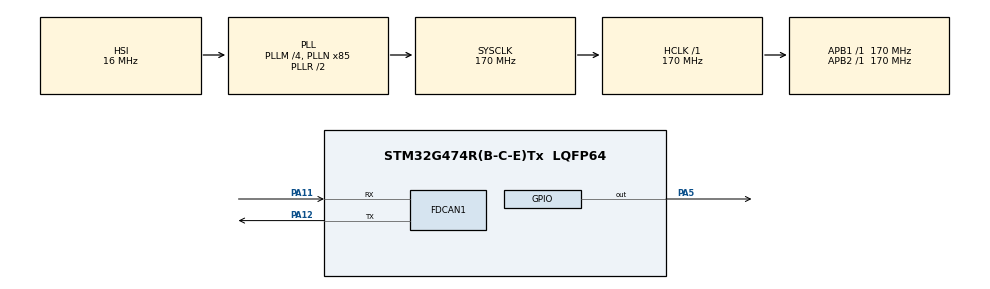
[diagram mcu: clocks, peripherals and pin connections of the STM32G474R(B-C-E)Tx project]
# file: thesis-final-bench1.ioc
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FDCAN1.CalculateBaudRateNominal=500000
FDCAN1.CalculateTimeBitNominal=2000
FDCAN1.CalculateTimeQuantumNominal=100.0
FDCAN1.NominalPrescaler=17
FDCAN1.NominalTimeSeg1=15
FDCAN1.NominalTimeSeg2=4
Mcu.Family=STM32G4
Mcu.Name=STM32G474R(B-C-E)Tx
Mcu.Package=LQFP64
NVIC.PriorityGroup=NVIC_PRIORITYGROUP_4
PA11.Mode=FDCAN_Activate
PA11.Signal=FDCAN1_RX
PA12.Mode=FDCAN_Activate
PA12.Signal=FDCAN1_TX
PA5.Signal=GPIO_Output
ProjectManager.HeapSize=0x200
ProjectManager.StackSize=0x400
ProjectManager.TargetToolchain=STM32CubeIDE
RCC.ADC12Freq_Value=170000000
RCC.ADC345Freq_Value=170000000
RCC.AHBFreq_Value=170000000
RCC.APB1Freq_Value=170000000
RCC.APB1TimFreq_Value=170000000
RCC.APB2Freq_Value=170000000
RCC.APB2TimFreq_Value=170000000
RCC.CortexFreq_Value=170000000
RCC.EXTERNAL_CLOCK_VALUE=12288000
RCC.HCLKFreq_Value=170000000
RCC.HSE_VALUE=8000000
RCC.HSI48_VALUE=48000000
RCC.HSI_VALUE=16000000
RCC.LSE_VALUE=32768
RCC.PLLM=RCC_PLLM_DIV4
RCC.PLLN=85
RCC.SYSCLKFreq_VALUE=170000000
RCC.SYSCLKSource=RCC_SYSCLKSOURCE_PLLCLK
RCC.USBFreq_Value=170000000
RCC.VCOOutputFreq_Value=340000000
VP_SYS_VS_DBSignals.Mode=DisableDeadBatterySignals
board=custom

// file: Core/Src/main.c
/* USER CODE BEGIN Header */
/**
  ******************************************************************************
  * @file           : main.c
  * @brief          : Main program body
  ******************************************************************************
  * @attention
  *
  * Copyright (c) 2026 STMicroelectronics.
  * All rights reserved.
  *
  * This software is licensed under terms that can be found in the LICENSE file
  * in the root directory of this software component.
  * If no LICENSE file comes with this software, it is provided AS-IS.
  *
  ******************************************************************************
  */
/* USER CODE END Header */
#include "main.h"

/* USER CODE BEGIN Includes */
#include "can.h"
#include "scheduler.h"
#include "com_manager.h"
#include "diagnostics.h"
#include "motor_control.h"

/* USER CODE END Includes */

FDCAN_HandleTypeDef hfdcan1;

void SystemClock_Config(void);
static void MX_GPIO_Init(void);
static void MX_FDCAN1_Init(void);

int main(void)
{

  /* MCU Configuration--------------------------------------------------------*/

  /* Reset of all peripherals, Initializes the Flash interface and the Systick. */
  HAL_Init();

  /* Configure the system clock */
  SystemClock_Config();

  /* Initialize all configured peripherals */
  MX_GPIO_Init();
  MX_FDCAN1_Init();
  /* USER CODE BEGIN 2 */
  CAN_Init();
  Scheduler_Init();
  Diagnostics_Init();
  App_MotorControl_Init();
  /* USER CODE END 2 */

  /* Infinite loop */
  /* USER CODE BEGIN WHILE */
  float actual_speed_rpm = 1500.0f; // Mocking physical encoder feedback for now

  while (1)
  {
      // --- 10ms TASK: Motor Control & Inputs ---
      if (Scheduler_Is10msTaskDue())
      {
          // 1. Execute the PI Controller Loop
          App_MotorControl_Task();

          // 2. Poll for incoming CAN commands (non-blocking)
          CAN_Message_t rx_msg;
          if (CAN_Receive(&rx_msg))
          {
              // If ID 0x200 arrives, decode the 4-byte payload into a float target speed
              if (rx_msg.id == 0x200 && rx_msg.dlc >= 4)
              {
                  HAL_GPIO_WritePin(GPIOA, GPIO_PIN_5, GPIO_PIN_SET); // LED ON (Command Received)

                  typedef union { float f; uint8_t bytes[4]; } FloatConverter_t;
                  FloatConverter_t conv;

                  // Assuming Big Endian payload from Cangaroo to match your TX logic
                  conv.bytes[3] = rx_msg.data[0];
                  conv.bytes[2] = rx_msg.data[1];
                  conv.bytes[1] = rx_msg.data[2];
                  conv.bytes[0] = rx_msg.data[3];

                  App_MotorControl_SetTargetSpeed(conv.f);
              }
          }
      }

      // --- 100ms TASK: Telemetry & Broadcast ---
      if (Scheduler_Is100msTaskDue())
      {
          // Broadcast the speed via com_manager
          COM_SendMotorSpeed(actual_speed_rpm);

          // Mock the motor accelerating to simulate physical feedback
          actual_speed_rpm += 5.5f;
      }
    /* USER CODE END WHILE */

  }
}

void SystemClock_Config(void)
{
  RCC_OscInitTypeDef RCC_OscInitStruct = {0};
  RCC_ClkInitTypeDef RCC_ClkInitStruct = {0};

  /** Configure the main internal regulator output voltage
  */
  HAL_PWREx_ControlVoltageScaling(PWR_REGULATOR_VOLTAGE_SCALE1_BOOST);

  /** Initializes the RCC Oscillators according to the specified parameters
  * in the RCC_OscInitTypeDef structure.
  */
  RCC_OscInitStruct.OscillatorType = RCC_OSCILLATORTYPE_HSI;
  RCC_OscInitStruct.HSIState = RCC_HSI_ON;
  RCC_OscInitStruct.HSICalibrationValue = RCC_HSICALIBRATION_DEFAULT;
  RCC_OscInitStruct.PLL.PLLState = RCC_PLL_ON;
  RCC_OscInitStruct.PLL.PLLSource = RCC_PLLSOURCE_HSI;
  RCC_OscInitStruct.PLL.PLLM = RCC_PLLM_DIV4;
  RCC_OscInitStruct.PLL.PLLN = 85;
  RCC_OscInitStruct.PLL.PLLP = RCC_PLLP_DIV2;
  RCC_OscInitStruct.PLL.PLLQ = RCC_PLLQ_DIV2;
  RCC_OscInitStruct.PLL.PLLR = RCC_PLLR_DIV2;
  if (HAL_RCC_OscConfig(&RCC_OscInitStruct) != HAL_OK)
  {
    Error_Handler();
  }

  /** Initializes the CPU, AHB and APB buses clocks
  */
  RCC_ClkInitStruct.ClockType = RCC_CLOCKTYPE_HCLK|RCC_CLOCKTYPE_SYSCLK
                              |RCC_CLOCKTYPE_PCLK1|RCC_CLOCKTYPE_PCLK2;
  RCC_ClkInitStruct.SYSCLKSource = RCC_SYSCLKSOURCE_PLLCLK;
  RCC_ClkInitStruct.AHBCLKDivider = RCC_SYSCLK_DIV1;
  RCC_ClkInitStruct.APB1CLKDivider = RCC_HCLK_DIV1;
  RCC_ClkInitStruct.APB2CLKDivider = RCC_HCLK_DIV1;

  if (HAL_RCC_ClockConfig(&RCC_ClkInitStruct, FLASH_LATENCY_4) != HAL_OK)
  {
    Error_Handler();
  }
}

static void MX_FDCAN1_Init(void)
{

  hfdcan1.Instance = FDCAN1;
  hfdcan1.Init.ClockDivider = FDCAN_CLOCK_DIV1;
  hfdcan1.Init.FrameFormat = FDCAN_FRAME_CLASSIC;
  hfdcan1.Init.Mode = FDCAN_MODE_NORMAL;
  hfdcan1.Init.AutoRetransmission = DISABLE;
  hfdcan1.Init.TransmitPause = DISABLE;
  hfdcan1.Init.ProtocolException = DISABLE;
  hfdcan1.Init.NominalPrescaler = 17;
  hfdcan1.Init.NominalSyncJumpWidth = 1;
  hfdcan1.Init.NominalTimeSeg1 = 15;
  hfdcan1.Init.NominalTimeSeg2 = 4;
  hfdcan1.Init.DataPrescaler = 1;
  hfdcan1.Init.DataSyncJumpWidth = 1;
  hfdcan1.Init.DataTimeSeg1 = 1;
  hfdcan1.Init.DataTimeSeg2 = 1;
  hfdcan1.Init.StdFiltersNbr = 0;
  hfdcan1.Init.ExtFiltersNbr = 0;
  hfdcan1.Init.TxFifoQueueMode = FDCAN_TX_FIFO_OPERATION;
  if (HAL_FDCAN_Init(&hfdcan1) != HAL_OK)
  {
    Error_Handler();
  }

}

static void MX_GPIO_Init(void)
{
  GPIO_InitTypeDef GPIO_InitStruct = {0};

  /* GPIO Ports Clock Enable */
  __HAL_RCC_GPIOA_CLK_ENABLE();

  /*Configure GPIO pin Output Level */
  HAL_GPIO_WritePin(GPIOA, GPIO_PIN_5, GPIO_PIN_RESET);

  /*Configure GPIO pin : PA5 */
  GPIO_InitStruct.Pin = GPIO_PIN_5;
  GPIO_InitStruct.Mode = GPIO_MODE_OUTPUT_PP;
  GPIO_InitStruct.Pull = GPIO_NOPULL;
  GPIO_InitStruct.Speed = GPIO_SPEED_FREQ_LOW;
  HAL_GPIO_Init(GPIOA, &GPIO_InitStruct);

}

void Error_Handler(void)
{
  __disable_irq();
  while (1)
  {
  }
}
